# K1921VK01T register map
Vendor: NIIET; Series: K1921VKx; File version: 2.2
CPU: CM4 r0p1, little endian, MPU, FPU, 3 interrupt priority bits
Registers are 32-bit, read-write, reset 0x0 unless marked. A register's access mark holds for its fields unless they carry their own. Offsets are from the block's base; [hi:lo] are bit positions.

## NT_QEP0 — QEP controller registers
Base 0xA001A000
Same registers: NT_QEP1 0xA001B000
0x00 QPOSCNT — Position count register
0x04 QPOSINIT — Shadow count register
0x08 QPOSMAX — Period register
0x0C QPOSCMP — Count compare position reg
0x10 QPOSILAT ro — Register meaning count position
0x14 QPOSSLAT ro — Strobe register
0x18 QPOSLAT ro — Time event register
0x1C QUTMR — Time reading timer register
0x20 QUPRD — Period time reading timer register
0x24 QWDTMR — Watchdog timer register
0x28 QWDPRD — Period watchdog timer register
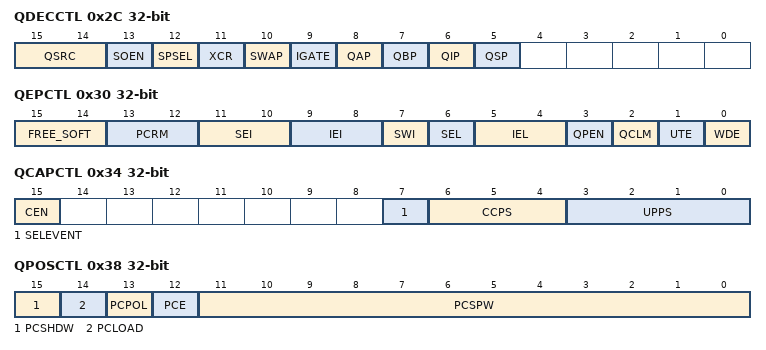
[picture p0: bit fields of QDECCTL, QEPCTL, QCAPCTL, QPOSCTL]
0x2C QDECCTL — Input control register
  [15:14] QSRC
    0=quadrature mode; 1=count/direction mode; 2=Up (count up); 3=Down (count down)
  [13] SOEN — enable PCSOUT
  [12] SPSEL — index/strobe output
  [11] XCR — edge selector
  [10] SWAP — trade places QEPA and QEPB
  [9] IGATE — strobing input signal
  [8] QAP — inv. QEPA
  [7] QBP — inv. QEPB
  [6] QIP — inv. QEPI
  [5] QSP — inversion QEPS
0x30 QEPCTL — Quadrature decoder control register
  [15:14] FREE_SOFT
    0=Stop (counters are blocked); 1=StopAtOvf (stop after overflow); 2=Free (no count stop in debug mode)
  [13:12] PCRM
    0=Ind (reset on index); 1=PosMax (reset on max position count); 2=FirstInd (reset on the first index); 3=Time (reset on time counter)
  [11:10] SEI
    0=no initialization; 2=QEPSPos (init on posedge QEPI); 3=QEPSDir (init depends on direction - on posedge if direction is up, on negedge if direction is down)
  [9:8] IEI
    0=no initialization; 2=QEPIPos (init on posedge QEPI); 3=QEPINeg (init on negedge QEPI)
  [7] SWI — enable positioncount
  [6] SEL — sttobevent
  [5:4] IEL
    0=NoLatch (no position counter latch); 1=IndPos (latch on index signal posedge); 2=IndNeg (latch on index signal negedge); 3=IndMark (latch on index marker)
  [3] QPEN — reset meaning countposition
  [2] QCLM — save countposition meaning
  [1] UTE — enable time reading timer
  [0] WDE — enable watchdog timer
0x34 QCAPCTL — Capture register
  [15] CEN — enable decoder
  [7] SELEVENT — Reset timer
  [6:4] CCPS
    0=Disable (no divider); 1=Div2 (sysclk divided by 2); 2=Div4 (sysclk divided by 4); 3=Div8 (sysclk divided by 8); 4=Div16 (sysclk divided by 16); 5=Div32 (sysclk divided by 32); 6=Div64 (sysclk divided by 64); 7=Div128 (sysclk divided by 128)
  [3:0] UPPS
    0=Disable (quad signal not divided); 1=Div2 (quad signal divided by 2); 2=Div4 (quad signal divided by 4); 3=Div8 (quad signal divided by 8); 4=Div16 (quad signal divided by 16); 5=Div32 (quad signal divided by 32); 6=Div64 (quad signal divided by 64); 7=Div128 (quad signal divided by 128); 8=Div256 (quad signal divided by 256); 9=Div512 (quad signal divided by 512); 10=Div1024 (quad signal divided by 1024); 11=Div2048 (quad signal divided by 2048)
0x38 QPOSCTL — Register countposition control
  [15] PCSHDW — Lazy load
  [14] PCLOAD — Lazy write rate
  [13] PCPOL — polarity synchout
  [12] PCE — enable compare
  [11:0] PCSPW
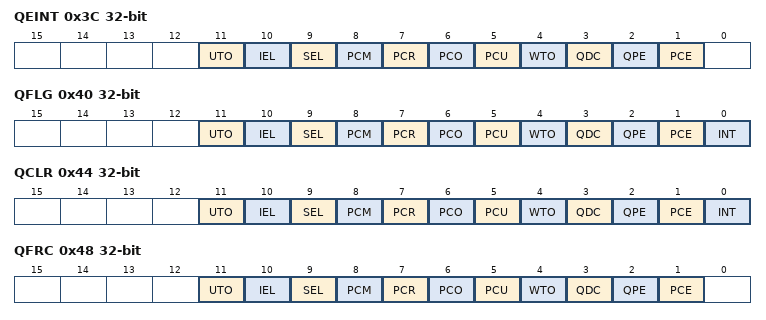
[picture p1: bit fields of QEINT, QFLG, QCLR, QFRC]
0x3C QEINT — Interrupt mask
  [11] UTO — outflow time int
  [10] IEL — Index int
  [9] SEL — Strobe int
  [8] PCM — enable compare int
  [7] PCR — ready compare int
  [6] PCO — interrupt countmax
  [5] PCU — interrupt countmin
  [4] WTO — Watchdog interrupt
  [3] QDC — Change direction interrupt
  [2] QPE — errorphase interrupt
  [1] PCE — enable countpos interrupt
0x40 QFLG ro — Flag interrupt
  [11] UTO — outflow time int flag
  [10] IEL — Index int flag
  [9] SEL — Strobe int flag
  [8] PCM — enable compare int flag
  [7] PCR — ready compare int flag
  [6] PCO — interrupt countmax flag
  [5] PCU — interrupt countmin flag
  [4] WTO — Watchdog interrupt flag
  [3] QDC — Change direction interrupt flag
  [2] QPE — errorphase interrupt flag
  [1] PCE — enable countpos interrupt flag
  [0] INT — outint flag
0x44 QCLR — Reset interrupt
  [11] UTO — reset flag
  [10] IEL — reset flag
  [9] SEL — reset flag
  [8] PCM — reset flag
  [7] PCR — reset flag
  [6] PCO — reset flag
  [5] PCU — reset flag
  [4] WTO — reset flag
  [3] QDC — reset flag
  [2] QPE — reset flag
  [1] PCE — reset flag
  [0] INT — reset flag
0x48 QFRC — Emulation interrupt
  [11] UTO — enable flag
  [10] IEL — enable flag
  [9] SEL — enable flag
  [8] PCM — enable flag
  [7] PCR — enable flag
  [6] PCO — enable flag
  [5] PCU — enable flag
  [4] WTO — enable flag
  [3] QDC — enable flag
  [2] QPE — enable flag
  [1] PCE — enable flag
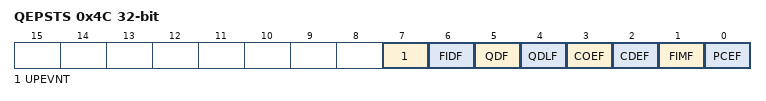
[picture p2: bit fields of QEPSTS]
0x4C QEPSTS — Status interrupt
  [7] UPEVNT — Flag timer time samples
  [6] FIDF — rotation of the rotor shaft
  [5] QDF — rotation of the rotor shaft
  [4] QDLF — rotation of the rotor shaft
  [3] COEF — Flag Counter Overflow quadrature
  [2] CDEF — change rotation
  [1] FIMF — receiving impulse
  [0] PCEF — error position flag
0x50 QCTMR — Timer register
0x54 QCPRD — Period register
0x58 QCTMRLAT ro — Register Storage Timer
0x5C QCPRDLAT — Register Storage Period
0x70 INTCLR — Clear interrupt register
  [0] INT — Active interrupt by read, write 1 to clear interrupt
